AUTOSAR XML (schema 4-1-1)
package /Demo/Door
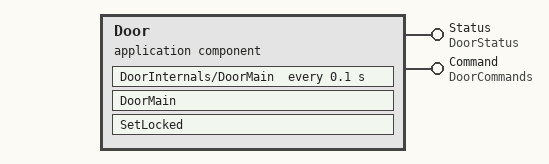
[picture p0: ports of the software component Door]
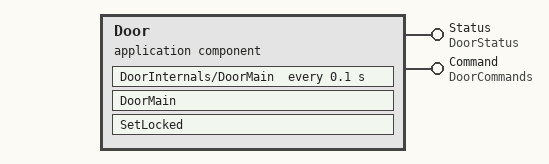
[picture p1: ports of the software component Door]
  application sw component type Door
    provide port Status: provided-interface=DoorStatus
    provide port Command: provided-interface=DoorCommands
    behavior DoorInternals: handle-termination-and-restart=NO-SUPPORT
      timing event timingEvent_0_1: start-on-event=DoorInternals/DoorMain, period=0.1
      operation invoked event Command_SetLock: start-on-event=DoorInternals/SetLocked, operation=Command.SetLock
      runnable DoorMain
        data-write-access:
          access dataWriteAccess_DoorMain_Status_Locked: accessed-variable=Status.Locked
          access dataWriteAccess_DoorMain_Status_Open: accessed-variable=Status.Open
      runnable SetLocked
  swc implementation DoorImplementation: programming-language=C, vendor-id=0, behavior=Door/DoorInternals
    code-descriptors:
      code src: artifact-descriptors=autosar-engineering-object={short-label=artifactDescriptor, category=artifactDescriptorCategory}
    resource consumption resourceConsumption
package /Demo/Services/IoHwAb
  impl type IoHwAb_SignalType_: implementation-data-type=uint32
  app type dummy_IoHwAb_SignalType_: category=VALUE
  data type mapping set dummyMappingSet: data-type-map{application-data-type=dummy_IoHwAb_SignalType_, implementation-data-type=IoHwAb_SignalType_}
  impl type SignalQuality: compu {0=IOHWAB_INIVAL, 1=IOHWAB_ERR, 2=IOHWAB_BAD, 3=IOHWAB_GOOD}, implementation-data-type=uint8
  impl type DigitalLevel: compu {0=IOHWAB_LOW, 1=IOHWAB_HIGH}, implementation-data-type=uint8
  client server interface DigitalServiceWrite: is-service=true
    operation Write: possible-error=[E_OK, E_NOT_OK]
      arg Level: type=DigitalLevel, direction=IN
    error E_OK: error-code=0
    error E_NOT_OK: error-code=1
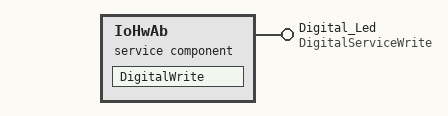
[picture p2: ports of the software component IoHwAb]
  service sw component type IoHwAb
    provide port Digital_Led: provided-interface=DigitalServiceWrite
    behavior IoHwAbBehavior: handle-termination-and-restart=NO-SUPPORT, port-api-option{port-defined-argument-value{value=IoHwAb_SignalType_:0, value-type=IoHwAb_SignalType_}, port=Digital_Led}
      operation invoked event Digital_Led_Write: start-on-event=DigitalWrite, operation=Digital_Led.Write
      runnable DigitalWrite: can-be-invoked-concurrently=true, symbol=IoHwAb_Digital_Write
  swc implementation IoHwAbImpl: programming-language=C, vendor-id=0, behavior=IoHwAbBehavior
    code-descriptors:
      code src: artifact-descriptors=autosar-engineering-object={short-label=artifactDescriptor, category=artifactDescriptorCategory}
    resource consumption resourceConsumption
package /Demo/Interfaces
  sender receiver interface DoorStatus
    data Locked: type=boolean
    data Open: type=boolean
  client server interface DoorCommands
    operation SetLock
      arg Locked: type=boolean, direction=IN
  sender receiver interface CombinedStatus
    4 x data, all with type=boolean:
      LockedLeft
      OpenLeft
      LockedRight
      OpenRight
package /Demo/DoorControl
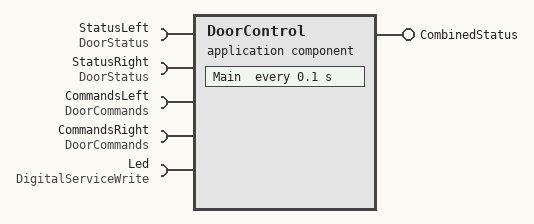
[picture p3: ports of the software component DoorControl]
  application sw component type DoorControl
    5 x require port:
      StatusLeft: required-interface=DoorStatus
      StatusRight: required-interface=DoorStatus
      CommandsLeft: required-interface=DoorCommands
      CommandsRight: required-interface=DoorCommands
      Led: required-interface=DigitalServiceWrite
    provide port CombinedStatus: provided-interface=CombinedStatus
    behavior DoorControlInternals: handle-termination-and-restart=NO-SUPPORT
      timing event timingEvent_0_1: start-on-event=Main, period=0.1
      runnable Main
        data-read-access:
          4 x access:
            dataReadAccess_Main_StatusLeft_Locked: accessed-variable=StatusLeft.Locked
            dataReadAccess_Main_StatusLeft_Open: accessed-variable=StatusLeft.Open
            dataReadAccess_Main_StatusRight_Locked: accessed-variable=StatusRight.Locked
            dataReadAccess_Main_StatusRight_Open: accessed-variable=StatusRight.Open
        data-write-access:
          4 x access:
            dataWriteAccess_Main_CombinedStatus_LockedLeft: accessed-variable=CombinedStatus.LockedLeft
            dataWriteAccess_Main_CombinedStatus_OpenLeft: accessed-variable=CombinedStatus.OpenLeft
            dataWriteAccess_Main_CombinedStatus_LockedRight: accessed-variable=CombinedStatus.LockedRight
            dataWriteAccess_Main_CombinedStatus_OpenRight: accessed-variable=CombinedStatus.OpenRight
        sync call serverCallPoint_Main_CommandsLeft_SetLock: operation=CommandsLeft.SetLock, timeout=0.0
        sync call serverCallPoint_Main_CommandsRight_SetLock: operation=CommandsRight.SetLock, timeout=0.0
        sync call serverCallPoint_Main_Led_Write: operation=Led.Write, timeout=0.0
  swc implementation DoorControlImplementation: programming-language=C, vendor-id=0, behavior=DoorControlInternals
    code-descriptors:
      code src: artifact-descriptors=autosar-engineering-object={short-label=artifactDescriptor, category=artifactDescriptorCategory}
    resource consumption resourceConsumption
package /Demo/EDC
  composition sw component type EDC
    provide port CombinedStatus: provided-interface=CombinedStatus
    4 x component:
      DoorLeft: type=Door/Door
      DoorRight: type=Door/Door
      Control: type=DoorControl
      IO: type=IoHwAb
    connect DoorLeft.Command -> Control.CommandsLeft  # The connector
    connect DoorRight.Command -> Control.CommandsRight
    connect DoorLeft.Status -> Control.StatusLeft
    connect DoorRight.Status -> Control.StatusRight
    connect IO.Digital_Led -> Control.Led
    delegate Control.CombinedStatus <-> outer port EDC/CombinedStatus
  system EDCEcuExtract: category=ECU_EXTRACT
    system mapping ImplementationMappings
      sw-impl-mappings:
        4 x swc to impl mapping:
          DoorLeftMapping: component-implementation=Door/DoorImplementation, component=EDCPrototype.DoorLeft
          DoorRightMapping: component-implementation=Door/DoorImplementation, component=EDCPrototype.DoorRight
          ControlMapping: component-implementation=DoorControlImplementation, component=EDCPrototype.Control
          IOMapping: component-implementation=IoHwAbImpl, component=EDCPrototype.IO
    system mapping SignalMappings
      data-mappings:
        data-element=EDCPrototype.CombinedStatus.LockedLeft, system-signal=CombinedStatusLockedLeftSSig
        data-element=EDCPrototype.CombinedStatus.OpenLeft, system-signal=CombinedStatusOpenLeftSSig
        data-element=EDCPrototype.CombinedStatus.LockedRight, system-signal=CombinedStatusLockedRightSSig
        data-element=EDCPrototype.CombinedStatus.OpenRight, system-signal=CombinedStatusOpenRightSSig
    root-software-compositions:
      root sw composition prototype EDCPrototype: software-composition=EDC
package /Demo/EDC/Communication
  pdu CombinedStatusLockedLeftIPdu
    signal CombinedStatusLockedLeftISig: system signal CombinedStatusLockedLeftSSig
  pdu CombinedStatusOpenLeftIPdu
    signal CombinedStatusOpenLeftISig: system signal CombinedStatusOpenLeftSSig
  pdu CombinedStatusLockedRightIPdu
    signal CombinedStatusLockedRightISig: system signal CombinedStatusLockedRightSSig
  pdu CombinedStatusOpenRightIPdu
    signal CombinedStatusOpenRightISig: system signal CombinedStatusOpenRightSSig
package /Demo/Motor
  application sw component type Door
    provide port Status: provided-interface=DoorStatus
    provide port Command: provided-interface=DoorCommands
    behavior DoorInternals: handle-termination-and-restart=NO-SUPPORT
      timing event timingEvent_0_1: start-on-event=DoorInternals/DoorMain, period=0.1
      operation invoked event Command_SetLock: start-on-event=DoorInternals/SetLocked, operation=Command.SetLock
      runnable DoorMain
        data-write-access:
          access dataWriteAccess_DoorMain_Status_Locked: accessed-variable=Status.Locked
          access dataWriteAccess_DoorMain_Status_Open: accessed-variable=Status.Open
      runnable SetLocked
  swc implementation DoorImplementation: programming-language=C, vendor-id=0, behavior=Door/DoorInternals
    code-descriptors:
      code src: artifact-descriptors=autosar-engineering-object={short-label=artifactDescriptor, category=artifactDescriptorCategory}
    resource consumption resourceConsumption
